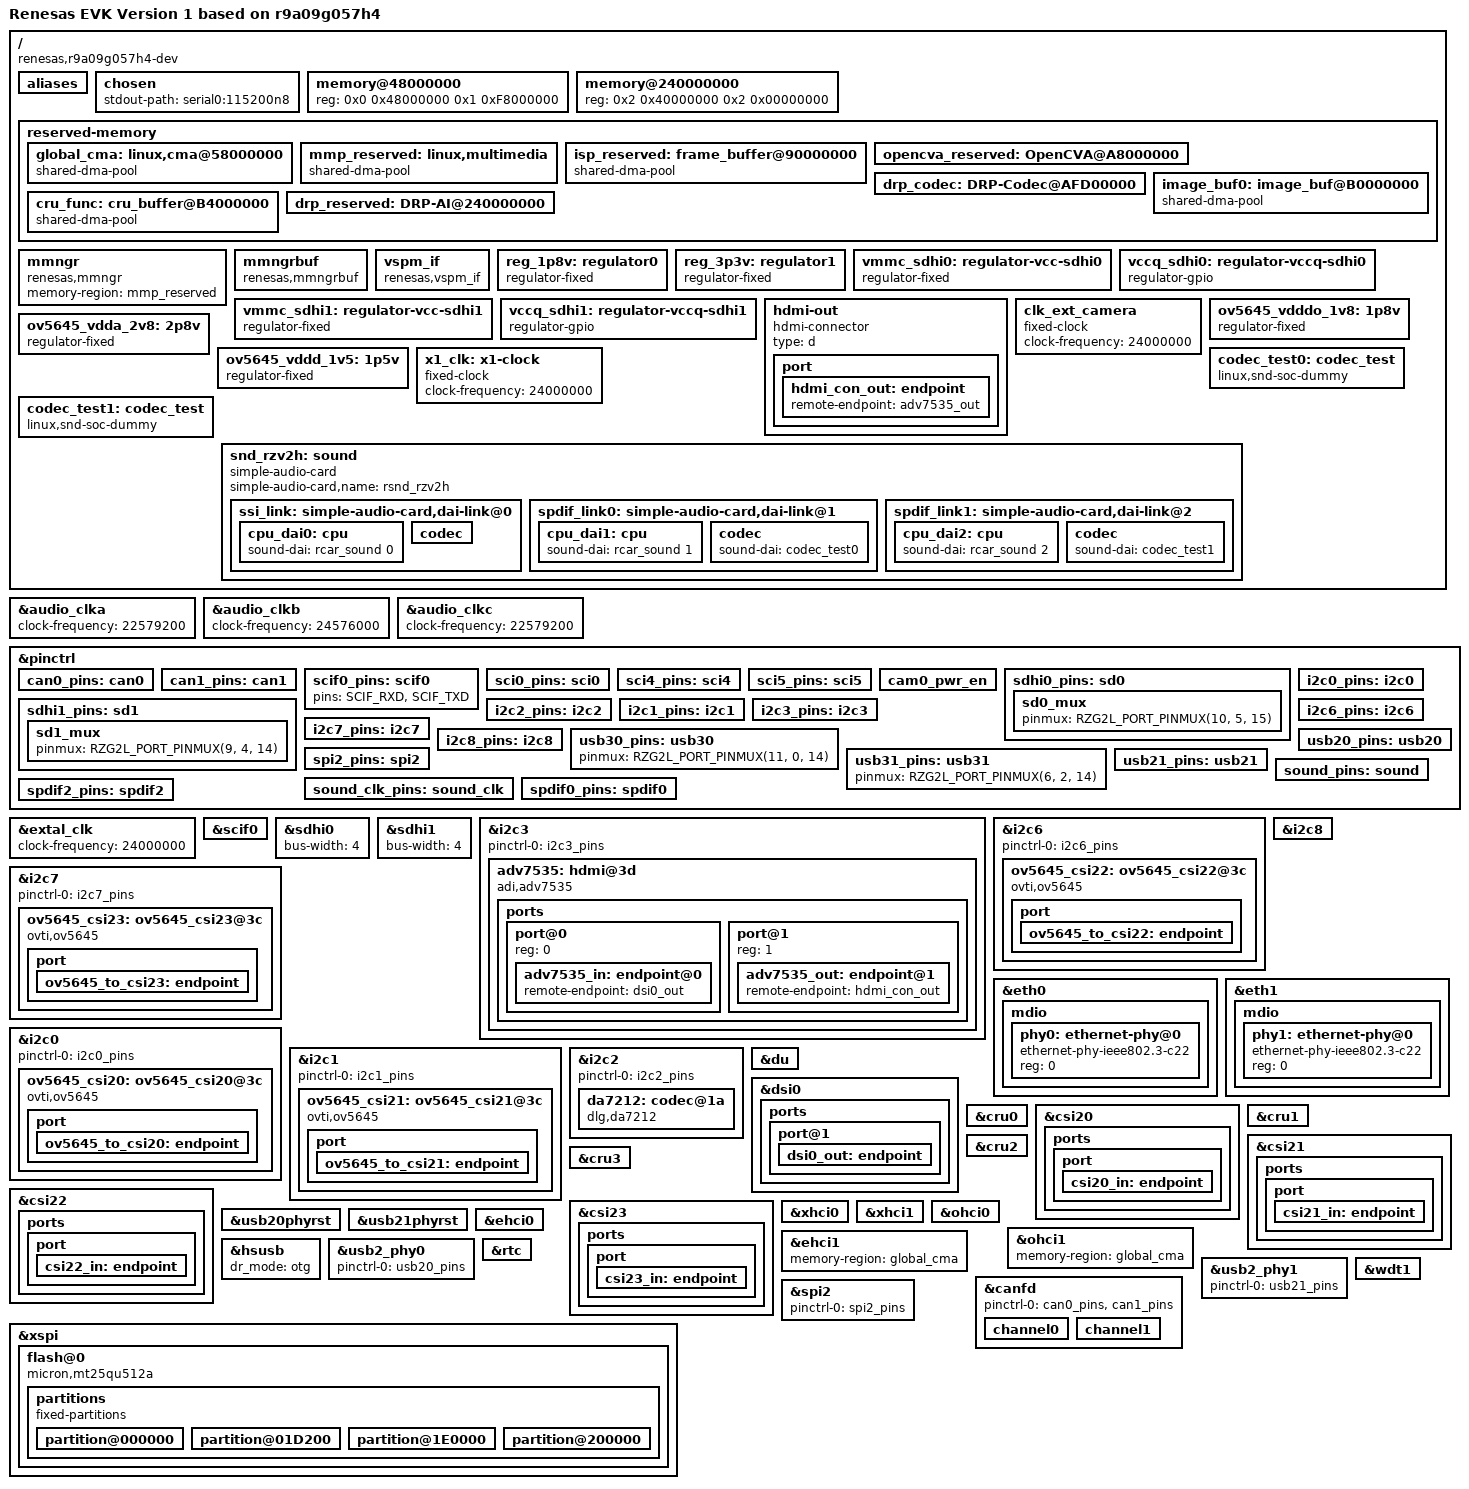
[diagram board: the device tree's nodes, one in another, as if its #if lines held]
// SPDX-License-Identifier: (GPL-2.0-only OR BSD-2-Clause)
/*
 * Device Tree Source for the RZ/V2H EVK Version 1 board
 *
 * Copyright (C) 2023 Renesas Electronics Corp.
 */

/dts-v1/;
#include <dt-bindings/gpio/gpio.h>
#include "r9a09g057.dtsi"
#include <dt-bindings/pinctrl/rzv2h-pinctrl.h>
#include "r9a09g057-u-boot.dtsi"

/ {
	model = "Renesas EVK Version 1 based on r9a09g057h4";
	compatible = "renesas,r9a09g057h4-dev", "renesas,r9a09g057h4", "renesas,r9a09g057";

	aliases {
		serial0 = &scif0;
		mmc0 = &sdhi0;
		mmc1 = &sdhi1;
		i2c3 = &i2c3;
		i2c6 = &i2c6;
		i2c7 = &i2c7;
		i2c8 = &i2c8;
		spi0 = &xspi;
		ethernet0 = &eth0;
		ethernet1 = &eth1;
	};

	chosen {
		stdout-path = "serial0:115200n8";
	};

	memory@48000000 {
		device_type = "memory";
		/* first 128MB is reserved for secure area. */
		reg = <0x0 0x48000000 0x1 0xF8000000>;
	};

	memory@240000000 {
		device_type = "memory";
		reg = <0x2 0x40000000 0x2 0x00000000>;
	};

	reserved-memory {
		#address-cells = <2>;
		#size-cells = <2>;
		ranges;

		global_cma: linux,cma@58000000 {
			compatible = "shared-dma-pool";
			linux,cma-default;
			reusable;
			reg = <0x0 0x58000000 0x0 0x28000000>;
		};

		mmp_reserved: linux,multimedia {
			compatible = "shared-dma-pool";
			reusable;
			reg = <0x00000000 0x80000000 0x0 0x10000000>;
		};

		isp_reserved: frame_buffer@90000000 {
			compatible = "shared-dma-pool";
			reusable;
			reg = <0x0 0x90000000 0x0 0x18000000>;
		};

		opencva_reserved: OpenCVA@A8000000 {
			reusable;
			reg = <0x0 0xA8000000 0x0 0x7D00000>;
		};

		drp_codec: DRP-Codec@AFD00000 {
			reusable;
			reg = <0x0 0xAFD00000 0x0 0x300000>;
		};

		image_buf0: image_buf@B0000000 {
			compatible = "shared-dma-pool";
			reusable;
			reg = <0x0 0xB0000000 0x0 0x4000000>;
			label = "image_buf0";
		};

		cru_func: cru_buffer@B4000000 {
			compatible = "shared-dma-pool";
			reusable;
			reg = <0x0 0xB4000000 0x0 0x16400000>;
		};

		drp_reserved: DRP-AI@240000000 {
			reusable;
			reg = <0x2 0x40000000 0x0 0x20000000>;
		};
	};

	mmngr {
		compatible = "renesas,mmngr";
		memory-region = <&mmp_reserved>;
	};

	mmngrbuf {
		compatible = "renesas,mmngrbuf";
	};

	vspm_if {
		compatible = "renesas,vspm_if";
	};

	reg_1p8v: regulator0 {
		compatible = "regulator-fixed";

		regulator-name = "fixed-1.8V";
		regulator-min-microvolt = <1800000>;
		regulator-max-microvolt = <1800000>;
		regulator-boot-on;
		regulator-always-on;
	};

	reg_3p3v: regulator1 {
		compatible = "regulator-fixed";

		regulator-name = "fixed-3.3V";
		regulator-min-microvolt = <3300000>;
		regulator-max-microvolt = <3300000>;
		regulator-boot-on;
		regulator-always-on;
	};

	vmmc_sdhi0: regulator-vcc-sdhi0 {
		compatible = "regulator-fixed";

		regulator-name = "SDHI0 Vmmc";
		regulator-min-microvolt = <3300000>;
		regulator-max-microvolt = <3300000>;

		gpios = <&pinctrl RZG2L_GPIO(10, 1) GPIO_ACTIVE_HIGH>;
		enable-active-high;
	};

	vccq_sdhi0: regulator-vccq-sdhi0 {
		compatible = "regulator-gpio";

		regulator-name = "SDHI0 VccQ";
		regulator-min-microvolt = <1800000>;
		regulator-max-microvolt = <3300000>;

		gpios = <&pinctrl RZG2L_GPIO(10, 0) GPIO_ACTIVE_HIGH>;

		gpios-states = <0>;
		states = <3300000 0 1800000 1>;
	};

	vmmc_sdhi1: regulator-vcc-sdhi1 {
		compatible = "regulator-fixed";

		regulator-name = "SDHI1 Vmmc";
		regulator-min-microvolt = <3300000>;
		regulator-max-microvolt = <3300000>;

		gpios = <&pinctrl RZG2L_GPIO(10, 3) GPIO_ACTIVE_HIGH>;
		enable-active-high;
	};

	vccq_sdhi1: regulator-vccq-sdhi1 {
		compatible = "regulator-gpio";

		regulator-name = "SDHI1 VccQ";
		regulator-min-microvolt = <1800000>;
		regulator-max-microvolt = <3300000>;

		gpios = <&pinctrl RZG2L_GPIO(10, 2) GPIO_ACTIVE_HIGH>;

		gpios-states = <0>;
		states = <3300000 0 1800000 1>;
	};

	hdmi-out {
		compatible = "hdmi-connector";
		type = "d";

		port {
			hdmi_con_out: endpoint {
				remote-endpoint = <&adv7535_out>;
			};
		};
	};

	clk_ext_camera: clk_ext_camera {
		compatible = "fixed-clock";
		#clock-cells = <0>;
		clock-frequency = <24000000>;
	};

	ov5645_vdddo_1v8: 1p8v {
		compatible = "regulator-fixed";
		regulator-name = "camera_vdddo";
		regulator-min-microvolt = <1800000>;
		regulator-max-microvolt = <1800000>;
		regulator-always-on;
	};

	ov5645_vdda_2v8: 2p8v {
		compatible = "regulator-fixed";
		regulator-name = "camera_vdda";
		regulator-min-microvolt = <2800000>;
		regulator-max-microvolt = <2800000>;
		regulator-always-on;
	};

	ov5645_vddd_1v5: 1p5v {
		compatible = "regulator-fixed";
		regulator-name = "camera_vddd";
		regulator-min-microvolt = <1500000>;
		regulator-max-microvolt = <1500000>;
		regulator-always-on;
	};

	x1_clk: x1-clock {
		compatible = "fixed-clock";
		#clock-cells = <0>;
		clock-frequency = <24000000>;
	};

#if (!SEL_CAN01_HEADER)
	codec_test0: codec_test {
		compatible = "linux,snd-soc-dummy";
		#sound-dai-cells = <0>;
	};

	codec_test1: codec_test {
		compatible = "linux,snd-soc-dummy";
		#sound-dai-cells = <0>;
	};
#endif

	snd_rzv2h: sound {
		#address-cells = <1>;
		#size-cells = <0>;
		compatible = "simple-audio-card";
		simple-audio-card,name = "rsnd_rzv2h";
		status="okay";

		ssi_link: simple-audio-card,dai-link@0 {
			format = "i2s";
			reg = <0>;
			bitclock-master = <&cpu_dai0>;
			frame-master = <&cpu_dai0>;
			mclk-fs = <256>;

			cpu_dai0: cpu {
				sound-dai = <&rcar_sound 0>;
			};

			codec {
				sound-dai = <&da7212>;
				clocks = <&rcar_sound>;
			};
		};

#if (!SEL_CAN01_HEADER)
		spdif_link0: simple-audio-card,dai-link@1 {
			reg = <1>;
			bitclock-master = <&cpu_dai1>;
			frame-master = <&cpu_dai1>;

			cpu_dai1: cpu {
				sound-dai = <&rcar_sound 1>;
			};

			codec {
				sound-dai = <&codec_test0>;
			};
		};

		spdif_link1: simple-audio-card,dai-link@2 {
			reg = <1>;
			bitclock-master = <&cpu_dai2>;
			frame-master = <&cpu_dai2>;

			cpu_dai2: cpu {
				sound-dai = <&rcar_sound 2>;
			};

			codec {
				sound-dai = <&codec_test1>;
			};
		};
#endif
	};
};

&audio_clka {
	clock-frequency = <22579200>;
};

&audio_clkb {
	clock-frequency = <24576000>;
};

&audio_clkc {
	clock-frequency = <22579200>;
};

&pinctrl {
#if (SEL_CAN01_HEADER && !SEL_SCI4_CAN01)
	can0_pins: can0 {
		pinmux = <RZG2L_PORT_PINMUX(8, 0, 5)>, /* TX */
			 <RZG2L_PORT_PINMUX(8, 1, 5)>; /* RX */
	};

	can1_pins: can1 {
		pinmux = <RZG2L_PORT_PINMUX(8, 2, 5)>, /* TX */
			 <RZG2L_PORT_PINMUX(8, 3, 5)>; /* RX */
	};
#endif

	scif0_pins: scif0 {
		pins =  "SCIF_RXD", "SCIF_TXD";
	};

	sci0_pins: sci0 {
		pinmux = <RZG2L_PORT_PINMUX(5, 0, 1)>, /* SCI0_TXD_MOSI_SDA */
			 <RZG2L_PORT_PINMUX(5, 1, 1)>, /* SCI0_RXD_MISO_SCL */
			 <RZG2L_PORT_PINMUX(5, 2, 4)>, /* SCI0_CTS */
			 <RZG2L_PORT_PINMUX(5, 3, 2)>; /* SCI0_RTS */
	};

#if (SEL_CAN01_HEADER && SEL_SCI4_CAN01)
	sci4_pins: sci4 {
		pinmux = <RZG2L_PORT_PINMUX(8, 4, 6)>, /* SCI4_TXD_MOSI_SDA */
			 <RZG2L_PORT_PINMUX(8, 5, 6)>, /* SCI4_RXD_MISO_SCL */
			 <RZG2L_PORT_PINMUX(8, 0, 3)>, /* SCI4_CTS */
			 <RZG2L_PORT_PINMUX(8, 1, 1)>; /* SCI4_RTS */
	};
#endif

	sci5_pins: sci5 {
		pinmux = <RZG2L_PORT_PINMUX(8, 6, 6)>, /* SCI5_TXD_MOSI_SDA */
			 <RZG2L_PORT_PINMUX(8, 7, 6)>; /* SCI5_RXD_MISO_SCL */
	};

	/* cam0_pwr_en is used by Google Coral Camera from CSI20 and CSI21 */
	cam0_pwr_en {
		gpio-hog;
		gpios = <RZG2L_GPIO(11, 2) GPIO_ACTIVE_HIGH>;
		output-high;
		line-name = "cam0_pwr_en";
	};

	sdhi0_pins: sd0 {
		sd0_mux {
			pinmux = <RZG2L_PORT_PINMUX(10, 5, 15)>; /* SD0_CD */
		};
	};

	sdhi1_pins: sd1 {
		sd1_mux {
			pinmux = <RZG2L_PORT_PINMUX(9, 4, 14)>; /* SD1_CD */
		};
	};

	i2c0_pins: i2c0 {
		pinmux = <RZG2L_PORT_PINMUX(3, 0, 1)>, /* I2C0_SDA */
			 <RZG2L_PORT_PINMUX(3, 1, 1)>; /* I2C0_SCL */
	};

	i2c2_pins: i2c2 {
		pinmux = <RZG2L_PORT_PINMUX(2, 0, 4)>, /* I2C2_SDA */
			 <RZG2L_PORT_PINMUX(2, 1, 4)>; /* I2C2_SCL */
	};

	i2c1_pins: i2c1 {
		pinmux = <RZG2L_PORT_PINMUX(3, 2, 1)>, /* I2C1_SDA */
			 <RZG2L_PORT_PINMUX(3, 3, 1)>; /* I2C1_SCL */
	};

	i2c3_pins: i2c3 {
		pinmux = <RZG2L_PORT_PINMUX(3, 6, 1)>, /* I2C3_SDA */
			 <RZG2L_PORT_PINMUX(3, 7, 1)>; /* I2C3_SCL */
	};

	i2c6_pins: i2c6 {
		pinmux = <RZG2L_PORT_PINMUX(4, 4, 1)>, /* I2C6_SDA */
			 <RZG2L_PORT_PINMUX(4, 5, 1)>; /* I2C6_SCL */
	};

	i2c7_pins: i2c7 {
		pinmux = <RZG2L_PORT_PINMUX(4, 6, 1)>, /* I2C7_SDA */
			 <RZG2L_PORT_PINMUX(4, 7, 1)>; /* I2C7_SCL */
	};

	i2c8_pins: i2c8 {
		pinmux = <RZG2L_PORT_PINMUX(0, 6, 1)>, /* I2C8_SDA */
			 <RZG2L_PORT_PINMUX(0, 7, 1)>; /* I2C8_SCL */
	};

	usb30_pins: usb30 {
		pinmux = <RZG2L_PORT_PINMUX(11, 0, 14)>; /* VBUS */
	};

	usb31_pins: usb31 {
		pinmux = <RZG2L_PORT_PINMUX(6, 2, 14)>; /* VBUS */
	};

	usb20_pins: usb20 {
		pinmux = <RZG2L_PORT_PINMUX(9, 5, 14)>, /* VBUS */
			 <RZG2L_PORT_PINMUX(9, 6, 14)>; /* OVC */
	};

	usb21_pins: usb21 {
		pinmux = <RZG2L_PORT_PINMUX(6, 6, 14)>, /* VBUS */
			 <RZG2L_PORT_PINMUX(6, 7, 14)>; /* OVC */
	};

	spi2_pins: spi2 {
		pinmux = <RZG2L_PORT_PINMUX(11, 3, 5)>, /* MISO */
			 <RZG2L_PORT_PINMUX(11, 4, 5)>, /* MOSI */
			 <RZG2L_PORT_PINMUX(10, 7, 5)>, /* SSL */
			 <RZG2L_PORT_PINMUX(11, 5, 5)>; /* RSPCK */
	};

	sound_clk_pins: sound_clk {
		pinmux = <RZG2L_PORT_PINMUX(1, 0, 7)>, /* AUDIO_CLKB */
			 <RZG2L_PORT_PINMUX(1, 1, 7)>, /* AUDIO_CLKC */
			 <RZG2L_PORT_PINMUX(9, 7, 8)>; /* AUDIO_CLKOUT */
	};

	sound_pins: sound {
		pinmux = <RZG2L_PORT_PINMUX(1, 2, 7)>, /* SSI3_SCK */
			 <RZG2L_PORT_PINMUX(1, 3, 7)>, /* SSI3_WS */
			 <RZG2L_PORT_PINMUX(0, 4, 7)>, /* SSI3_SDATA */
			 <RZG2L_PORT_PINMUX(1, 5, 7)>; /* SSI4_SDATA */

	};

#if (!SEL_CAN01_HEADER)
	spdif0_pins: spdif0 {
		pinmux = <RZG2L_PORT_PINMUX(8, 0, 8)>, /* SPDIF0_OUT */
			 <RZG2L_PORT_PINMUX(8, 1, 8)>; /* SPDIF0_IN */
	};

	spdif2_pins: spdif2 {
		pinmux = <RZG2L_PORT_PINMUX(8, 2, 8)>, /* SPDIF2_OUT */
			 <RZG2L_PORT_PINMUX(8, 3, 8)>; /* SPDIF2_IN */
	};
#endif

};

&extal_clk {
	clock-frequency = <24000000>;
};

&scif0 {
	status = "okay";
};

&sdhi0 {
	bus-width = <4>;
	status = "okay";
};

&sdhi1 {
	bus-width = <4>;
	status = "okay";
};

&i2c3 {
	status = "okay";
};

&i2c6 {
	status = "okay";
};

&i2c7 {
	status = "okay";
};

&i2c8 {
	status = "okay";
};

&eth0 {
	status = "okay";
	phy-handle = <&phy0>;
	phy-mode = "rgmii-id";

	mdio {
		#address-cells = <1>;
		#size-cells = <0>;

		phy0: ethernet-phy@0 {
			compatible = "ethernet-phy-ieee802.3-c22";
			reg = <0>;
		};
	};
};

&eth1 {
	status = "okay";
	phy-handle = <&phy1>;
	phy-mode = "rgmii-id";

	mdio {
		#address-cells = <1>;
		#size-cells = <0>;

		phy1: ethernet-phy@0 {
			compatible = "ethernet-phy-ieee802.3-c22";
			reg = <0>;
		};
	};
};
&i2c0 {
	pinctrl-0 = <&i2c0_pins>;
	pinctrl-names = "default";

	status = "okay";

	ov5645_csi20: ov5645_csi20@3c {
		compatible = "ovti,ov5645";
		reg = <0x3c>;
		clock-names = "xclk";
		clocks = <&clk_ext_camera>;
		clock-frequency = <24000000>;
		vdddo-supply = <&ov5645_vdddo_1v8>;
		vdda-supply = <&ov5645_vdda_2v8>;
		vddd-supply = <&ov5645_vddd_1v5>;
		/* Set dummy enable gpio */
		enable-gpios = <&pinctrl RZG2L_GPIO(1, 6) GPIO_ACTIVE_HIGH>;
		reset-gpios = <&pinctrl RZG2L_GPIO(6, 4) GPIO_ACTIVE_LOW>;

		port {
			ov5645_to_csi20: endpoint {
				clock-lanes = <0>;
				data-lanes = <1 2>;
				remote-endpoint = <&csi20_in>;
			};
		};
	};
};

&i2c1 {
	pinctrl-0 = <&i2c1_pins>;
	pinctrl-names = "default";

	status = "okay";

	ov5645_csi21: ov5645_csi21@3c {
		compatible = "ovti,ov5645";
		reg = <0x3c>;
		clock-names = "xclk";
		clocks = <&clk_ext_camera>;
		clock-frequency = <24000000>;
		vdddo-supply = <&ov5645_vdddo_1v8>;
		vdda-supply = <&ov5645_vdda_2v8>;
		vddd-supply = <&ov5645_vddd_1v5>;
		/* Set dummy enable gpio */
		enable-gpios = <&pinctrl RZG2L_GPIO(1, 7) GPIO_ACTIVE_HIGH>;
		reset-gpios = <&pinctrl RZG2L_GPIO(6, 5) GPIO_ACTIVE_LOW>;

		port {
			ov5645_to_csi21: endpoint {
				clock-lanes = <0>;
				data-lanes = <1 2>;
				remote-endpoint = <&csi21_in>;
			};
		};
	};
};

&i2c2 {
	pinctrl-0 = <&i2c2_pins>;
	pinctrl-names = "default";

	status = "okay";

	da7212: codec@1a {
		compatible = "dlg,da7212";
		#sound-dai-cells = <0>;
		#address-cells = <1>;
		#size-cells = <0>;
		reg = <0x1a>;

		clocks = <&rcar_sound>;
		clock-names = "mclk";

		dlg,micbias1-lvl = <2500>;
		dlg,micbias2-lvl = <2500>;
		dlg,dmic-data-sel = "lrise_rfall";
		dlg,dmic-samplephase = "between_clkedge";
		dlg,dmic-clkrate = <3000000>;

		VDDA-supply = <&reg_1p8v>;
		VDDSP-supply = <&reg_3p3v>;
		VDDMIC-supply = <&reg_3p3v>;
		VDDIO-supply = <&reg_1p8v>;
	};
};

&i2c3 {
	pinctrl-0 = <&i2c3_pins>;
	pinctrl-names = "default";

	status = "okay";

	adv7535: hdmi@3d {
		compatible = "adi,adv7535";
		reg = <0x3d>;

		avdd-supply = <&reg_1p8v>;
		dvdd-supply = <&reg_1p8v>;
		pvdd-supply = <&reg_1p8v>;
		a2vdd-supply = <&reg_1p8v>;
		v3p3-supply = <&reg_3p3v>;
		v1p2-supply = <&reg_1p8v>;

		interrupt-parent = <&pinctrl>;
		interrupts = <RZG2L_GPIO(7, 1) IRQ_TYPE_LEVEL_LOW>;

		adi,dsi-lanes = <4>;

		ports {
			#address-cells = <1>;
			#size-cells = <0>;

			port@0 {
				reg = <0>;
				adv7535_in: endpoint@0 {
					remote-endpoint = <&dsi0_out>;
				};
			};

			port@1 {
				reg = <1>;
				adv7535_out: endpoint@1 {
				remote-endpoint = <&hdmi_con_out>;
				};
			};
		};
	};
};

&i2c6 {
	pinctrl-0 = <&i2c6_pins>;
	pinctrl-names = "default";

	status = "okay";

	ov5645_csi22: ov5645_csi22@3c {
		compatible = "ovti,ov5645";
		reg = <0x3c>;
		clock-names = "xclk";
		clocks = <&clk_ext_camera>;
		clock-frequency = <24000000>;
		vdddo-supply = <&ov5645_vdddo_1v8>;
		vdda-supply = <&ov5645_vdda_2v8>;
		vddd-supply = <&ov5645_vddd_1v5>;
		enable-gpios = <&pinctrl RZG2L_GPIO(6, 1) GPIO_ACTIVE_HIGH>;
		reset-gpios = <&pinctrl RZG2L_GPIO(9, 2) GPIO_ACTIVE_LOW>;

		port {
			ov5645_to_csi22: endpoint {
				clock-lanes = <0>;
				data-lanes = <1 2>;
				remote-endpoint = <&csi22_in>;
			};
		};
	};
};

&i2c7 {
	pinctrl-0 = <&i2c7_pins>;
	pinctrl-names = "default";

	status = "okay";

	ov5645_csi23: ov5645_csi23@3c {
		compatible = "ovti,ov5645";
		reg = <0x3c>;
		clock-names = "xclk";
		clocks = <&clk_ext_camera>;
		clock-frequency = <24000000>;
		vdddo-supply = <&ov5645_vdddo_1v8>;
		vdda-supply = <&ov5645_vdda_2v8>;
		vddd-supply = <&ov5645_vddd_1v5>;
		enable-gpios = <&pinctrl RZG2L_GPIO(6, 0) GPIO_ACTIVE_HIGH>;
		reset-gpios = <&pinctrl RZG2L_GPIO(9, 3) GPIO_ACTIVE_LOW>;

		port {
			ov5645_to_csi23: endpoint {
				clock-lanes = <0>;
				data-lanes = <1 2>;
				remote-endpoint = <&csi23_in>;
			};
		};
	};
};

&i2c8 {
	status = "okay";
};

&du {
	status = "okay";
};

&dsi0 {
	status = "okay";

	ports {
		port@1 {
			dsi0_out: endpoint {
				remote-endpoint = <&adv7535_in>;
				data-lanes = <1 2 3 4>;
			};
		};
	};
};

&cru0 {
	status = "okay";
};

&csi20 {
	status = "okay";

	ports {
		port {
			csi20_in: endpoint {
				clock-lanes = <0>;
				data-lanes = <1 2>;
				remote-endpoint = <&ov5645_to_csi20>;
			};
		};
	};
};

&cru1 {
	status = "okay";
};

&csi21 {
	status = "okay";

	ports {
		port {
			csi21_in: endpoint {
				clock-lanes = <0>;
				data-lanes = <1 2>;
				remote-endpoint = <&ov5645_to_csi21>;
			};
		};
	};
};

&cru2 {
	status = "okay";
};

&csi22 {
	status = "okay";

	ports {
		port {
			csi22_in: endpoint {
				clock-lanes = <0>;
				data-lanes = <1 2>;
				remote-endpoint = <&ov5645_to_csi22>;
			};
		};
	};
};

&cru3 {
	status = "okay";
};

&csi23 {
	status = "okay";

	ports {
		port {
			csi23_in: endpoint {
				clock-lanes = <0>;
				data-lanes = <1 2>;
				remote-endpoint = <&ov5645_to_csi23>;
			};
		};
	};
};

&xhci0 {
		pinctrl-0 = <&usb30_pins>;
		pinctrl-names = "default";

		memory-region = <&global_cma>;
		status = "okay";
};

&xhci1 {
		pinctrl-0 = <&usb31_pins>;
		pinctrl-names = "default";

		memory-region = <&global_cma>;
		status = "okay";
};

&usb20phyrst {
	status = "okay";
};

&usb21phyrst {
	status = "okay";
};

&ohci0 {
		memory-region = <&global_cma>;

		dr_mode = "otg";
		status = "okay";
};

&ohci1 {
		memory-region = <&global_cma>;

		status = "okay";
};

&ehci0 {
		memory-region = <&global_cma>;

		dr_mode = "otg";
		status = "okay";
};

&ehci1 {
		memory-region = <&global_cma>;

		status = "okay";
};

&hsusb {
		dr_mode = "otg";
		status = "okay";
};

&usb2_phy0 {
		pinctrl-0 = <&usb20_pins>;
		pinctrl-names = "default";

		status = "okay";
};

&usb2_phy1 {
		pinctrl-0 = <&usb21_pins>;
		pinctrl-names = "default";

		status = "okay";
};

#if (SEL_CAN01_HEADER && !SEL_SCI4_CAN01)
&canfd {
	pinctrl-0 = <&can0_pins &can1_pins>;
	pinctrl-names = "default";
	status = "okay";

	channel0 {
		status = "okay";
	};

	channel1 {
		status = "okay";
	};
};
#endif

&rtc {
	status = "okay";
};

&wdt1 {
	status = "okay";
};

&spi2 {
	pinctrl-0 = <&spi2_pins>;
	pinctrl-names = "default";

	status = "okay";
};

&xspi {
	status = "okay";

	flash@0 {
		compatible = "micron,mt25qu512a", "jedec,spi-nor";
		reg = <0>;
		m25p,fast-read;
		spi-max-frequency = <50000000>;
		spi-tx-bus-width = <1>;
		spi-rx-bus-width = <1>;

		partitions {
			compatible = "fixed-partitions";
			#address-cells = <1>;
			#size-cells = <1>;

			partition@000000 {
				label = "bl2";
				reg = <0x00000000 0x0001D200>;
				read-only;
			};

			partition@01D200 {
				label = "fip";
				reg = <0x0001D200 0x001C2E00>;
				read-only;
			};

			partition@1E0000 {
				label = "env";
				reg = <0x001E0000 0x00020000>;
				read-only;
			};

			partition@200000 {
				label = "test-area";
				reg = <0x00200000 0x00E00000>;
			};
		};
	};
};
